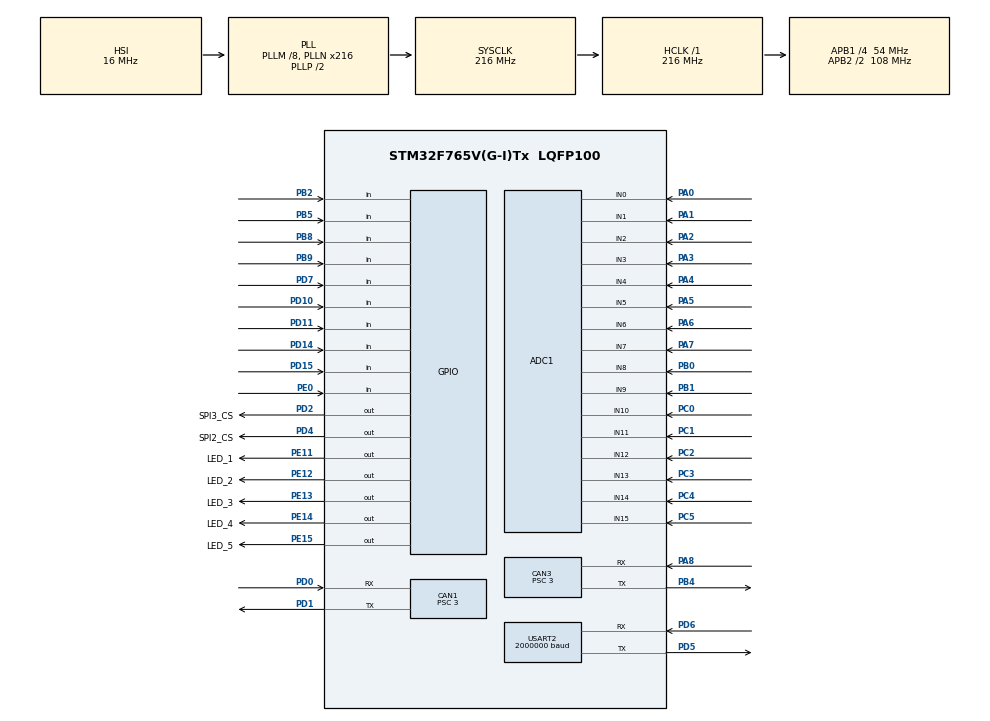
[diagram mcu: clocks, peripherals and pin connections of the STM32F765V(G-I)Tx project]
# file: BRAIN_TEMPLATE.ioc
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ADC1.Channel-6\#ChannelRegularConversion=ADC_CHANNEL_10
ADC1.NbrOfConversionFlag=1
ADC1.Rank-6\#ChannelRegularConversion=1
ADC1.SamplingTime-6\#ChannelRegularConversion=ADC_SAMPLETIME_3CYCLES
ADC1.master=1
CAN1.BS1=CAN_BS1_15TQ
CAN1.BS2=CAN_BS2_2TQ
CAN1.CalculateTimeQuantum=55.55555555555556
CAN1.NART=ENABLE
CAN1.Prescaler=3
CAN3.BS1=CAN_BS1_15TQ
CAN3.BS2=CAN_BS2_2TQ
CAN3.CalculateTimeQuantum=55.55555555555556
CAN3.NART=ENABLE
CAN3.Prescaler=3
Mcu.Family=STM32F7
Mcu.Name=STM32F765V(G-I)Tx
Mcu.Package=LQFP100
NVIC.CAN1_RX0_IRQn=true\:0\:0\:false\:true\:true\:2\:true\:true
NVIC.CAN1_RX1_IRQn=true\:0\:0\:false\:true\:true\:3\:true\:true
NVIC.CAN1_SCE_IRQn=true\:0\:0\:false\:true\:true\:4\:true\:true
NVIC.CAN1_TX_IRQn=true\:0\:0\:false\:true\:true\:1\:true\:true
NVIC.CAN3_RX0_IRQn=true\:0\:0\:false\:true\:true\:6\:true\:true
NVIC.CAN3_RX1_IRQn=true\:0\:0\:false\:true\:true\:8\:true\:true
NVIC.CAN3_SCE_IRQn=true\:0\:0\:false\:true\:true\:7\:true\:true
NVIC.CAN3_TX_IRQn=true\:0\:0\:false\:true\:true\:5\:true\:true
NVIC.PriorityGroup=NVIC_PRIORITYGROUP_4
PA0/WKUP.Signal=ADCx_IN0
PA1.Signal=ADCx_IN1
PA10.Signal=USART1_RX
PA13.Signal=SYS_JTMS-SWDIO
PA14.Signal=SYS_JTCK-SWCLK
PA2.Signal=ADCx_IN2
PA3.Signal=ADCx_IN3
PA4.Signal=ADCx_IN4
PA5.Signal=ADCx_IN5
PA6.Signal=ADCx_IN6
PA7.Signal=ADCx_IN7
PA8.Mode=Master
PA8.Signal=CAN3_RX
PA9.Signal=USART1_TX
PB0.Signal=ADCx_IN8
PB1.Signal=ADCx_IN9
PB10.Signal=I2C2_SCL
PB11.Signal=I2C2_SDA
PB14.Signal=SPI2_MISO
PB15.Signal=SPI2_MOSI
PB2.Signal=GPIO_Input
PB3.Signal=SYS_JTDO-SWO
PB4.Mode=Master
PB4.Signal=CAN3_TX
PB5.Signal=GPIO_Input
PB6.Signal=I2C1_SCL
PB7.Signal=I2C1_SDA
PB8.Signal=GPIO_Input
PB9.Signal=GPIO_Input
PC0.Signal=ADCx_IN10
PC1.Signal=ADCx_IN11
PC10.Signal=SPI3_SCK
PC11.Signal=SPI3_MISO
PC12.Signal=SPI3_MOSI
PC2.Signal=ADCx_IN12
PC3.Signal=ADCx_IN13
PC4.Signal=ADCx_IN14
PC5.Signal=ADCx_IN15
PC6.Signal=USART6_TX
PC7.Signal=USART6_RX
PD0.Mode=Master
PD0.Signal=CAN1_RX
PD1.Mode=Master
PD1.Signal=CAN1_TX
PD10.Signal=GPIO_Input
PD11.Signal=GPIO_Input
PD12.Signal=I2C4_SCL
PD13.Signal=I2C4_SDA
PD14.Signal=GPIO_Input
PD15.Signal=GPIO_Input
PD2.GPIO_Label=SPI3_CS
PD2.Signal=GPIO_Output
PD3.Signal=I2S2_CK
PD4.GPIO_Label=SPI2_CS
PD4.Signal=GPIO_Output
PD5.Mode=Asynchronous
PD5.Signal=USART2_TX
PD6.Mode=Asynchronous
PD6.Signal=USART2_RX
PD7.Signal=GPIO_Input
PE0.Signal=GPIO_Input
PE1.Signal=UART8_TX
PE11.GPIO_Label=LED_1
PE11.Signal=GPIO_Output
PE12.GPIO_Label=LED_2
PE12.Signal=GPIO_Output
PE13.GPIO_Label=LED_3
PE13.Signal=GPIO_Output
PE14.GPIO_Label=LED_4
PE14.Signal=GPIO_Output
PE15.GPIO_Label=LED_5
PE15.Signal=GPIO_Output
PE2.Signal=SPI4_SCK
PE5.Signal=SPI4_MISO
PE6.Signal=SPI4_MOSI
ProjectManager.HeapSize=0x200
ProjectManager.StackSize=0x400
ProjectManager.TargetToolchain=Makefile
RCC.AHBFreq_Value=216000000
RCC.APB1CLKDivider=RCC_HCLK_DIV4
RCC.APB1Freq_Value=54000000
RCC.APB1TimFreq_Value=108000000
RCC.APB2CLKDivider=RCC_HCLK_DIV2
RCC.APB2Freq_Value=108000000
RCC.APB2TimFreq_Value=216000000
RCC.CortexFreq_Value=216000000
RCC.HCLKFreq_Value=216000000
RCC.HSE_VALUE=25000000
RCC.HSI_VALUE=16000000
RCC.LSE_VALUE=32768
RCC.PLLM=8
RCC.PLLN=216
RCC.SYSCLKFreq_VALUE=216000000
RCC.SYSCLKSource=RCC_SYSCLKSOURCE_PLLCLK
RCC.USBFreq_Value=216000000
RCC.VCOOutputFreq_Value=432000000
SH.ADCx_IN0.0=ADC1_IN0,IN0
SH.ADCx_IN1.0=ADC1_IN1,IN1
SH.ADCx_IN10.0=ADC1_IN10,IN10
SH.ADCx_IN11.0=ADC1_IN11,IN11
SH.ADCx_IN12.0=ADC1_IN12,IN12
SH.ADCx_IN13.0=ADC1_IN13,IN13
SH.ADCx_IN14.0=ADC1_IN14,IN14
SH.ADCx_IN15.0=ADC1_IN15,IN15
SH.ADCx_IN2.0=ADC1_IN2,IN2
SH.ADCx_IN3.0=ADC1_IN3,IN3
SH.ADCx_IN4.0=ADC1_IN4,IN4
SH.ADCx_IN5.0=ADC1_IN5,IN5
SH.ADCx_IN6.0=ADC1_IN6,IN6
SH.ADCx_IN7.0=ADC1_IN7,IN7
SH.ADCx_IN8.0=ADC1_IN8,IN8
SH.ADCx_IN9.0=ADC1_IN9,IN9
USART2.BaudRate=2000000
USART2.VirtualMode-Asynchronous=VM_ASYNC
board=custom

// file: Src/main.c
/* USER CODE BEGIN Header */
/**
  ******************************************************************************
  * @file           : main.c
  * @brief          : Main program body
  ******************************************************************************
  * @attention
  *
  * <h2><center>&copy; Copyright (c) 2019 STMicroelectronics.
  * All rights reserved.</center></h2>
  *
  * This software component is licensed by ST under BSD 3-Clause license,
  * the "License"; You may not use this file except in compliance with the
  * License. You may obtain a copy of the License at:
  *                        opensource.org/licenses/BSD-3-Clause
  *
  ******************************************************************************
  */
/* USER CODE END Header */

#include "main.h"

ADC_HandleTypeDef hadc1;

CAN_HandleTypeDef hcan1;
CAN_HandleTypeDef hcan3;

UART_HandleTypeDef huart2;

void SystemClock_Config(void);
static void MX_GPIO_Init(void);
static void MX_ADC1_Init(void);
static void MX_CAN1_Init(void);
static void MX_CAN3_Init(void);
static void MX_USART2_UART_Init(void);
static void MX_NVIC_Init(void);

int main(void)
{

  /* MCU Configuration--------------------------------------------------------*/

  /* Reset of all peripherals, Initializes the Flash interface and the Systick. */
  HAL_Init();

  /* Configure the system clock */
  SystemClock_Config();

  /* Initialize all configured peripherals */
  MX_GPIO_Init();
  MX_ADC1_Init();
  MX_CAN1_Init();
  MX_CAN3_Init();
  MX_USART2_UART_Init();

  /* Initialize interrupts */
  MX_NVIC_Init();
  /* USER CODE BEGIN 2 */

  for(int i = 0; i < 10; i++){
    HAL_GPIO_TogglePin(LED_1_GPIO_Port, LED_1_Pin);
    HAL_GPIO_TogglePin(LED_2_GPIO_Port, LED_2_Pin);
    HAL_GPIO_TogglePin(LED_3_GPIO_Port, LED_3_Pin);
    HAL_GPIO_TogglePin(LED_4_GPIO_Port, LED_4_Pin);
    HAL_GPIO_TogglePin(LED_5_GPIO_Port, LED_5_Pin);
    HAL_Delay(50);
  }
  /* USER CODE END 2 */

  /* Infinite loop */
  /* USER CODE BEGIN WHILE */
  while (1)
  {
    HAL_GPIO_TogglePin(LED_1_GPIO_Port, LED_1_Pin);
    HAL_GPIO_TogglePin(LED_2_GPIO_Port, LED_2_Pin);
    HAL_GPIO_TogglePin(LED_3_GPIO_Port, LED_3_Pin);
    HAL_GPIO_TogglePin(LED_4_GPIO_Port, LED_4_Pin);
    HAL_GPIO_TogglePin(LED_5_GPIO_Port, LED_5_Pin);
    HAL_Delay(500);
    /* USER CODE END WHILE */

  }
}

void SystemClock_Config(void)
{
  RCC_OscInitTypeDef RCC_OscInitStruct = {0};
  RCC_ClkInitTypeDef RCC_ClkInitStruct = {0};
  RCC_PeriphCLKInitTypeDef PeriphClkInitStruct = {0};

  /** Configure the main internal regulator output voltage
  */
  __HAL_RCC_PWR_CLK_ENABLE();
  __HAL_PWR_VOLTAGESCALING_CONFIG(PWR_REGULATOR_VOLTAGE_SCALE1);
  /** Initializes the CPU, AHB and APB busses clocks
  */
  RCC_OscInitStruct.OscillatorType = RCC_OSCILLATORTYPE_HSI;
  RCC_OscInitStruct.HSIState = RCC_HSI_ON;
  RCC_OscInitStruct.HSICalibrationValue = RCC_HSICALIBRATION_DEFAULT;
  RCC_OscInitStruct.PLL.PLLState = RCC_PLL_ON;
  RCC_OscInitStruct.PLL.PLLSource = RCC_PLLSOURCE_HSI;
  RCC_OscInitStruct.PLL.PLLM = 8;
  RCC_OscInitStruct.PLL.PLLN = 216;
  RCC_OscInitStruct.PLL.PLLP = RCC_PLLP_DIV2;
  RCC_OscInitStruct.PLL.PLLQ = 2;
  if (HAL_RCC_OscConfig(&RCC_OscInitStruct) != HAL_OK)
  {
    Error_Handler();
  }
  /** Activate the Over-Drive mode
  */
  if (HAL_PWREx_EnableOverDrive() != HAL_OK)
  {
    Error_Handler();
  }
  /** Initializes the CPU, AHB and APB busses clocks
  */
  RCC_ClkInitStruct.ClockType = RCC_CLOCKTYPE_HCLK|RCC_CLOCKTYPE_SYSCLK
                              |RCC_CLOCKTYPE_PCLK1|RCC_CLOCKTYPE_PCLK2;
  RCC_ClkInitStruct.SYSCLKSource = RCC_SYSCLKSOURCE_PLLCLK;
  RCC_ClkInitStruct.AHBCLKDivider = RCC_SYSCLK_DIV1;
  RCC_ClkInitStruct.APB1CLKDivider = RCC_HCLK_DIV4;
  RCC_ClkInitStruct.APB2CLKDivider = RCC_HCLK_DIV2;

  if (HAL_RCC_ClockConfig(&RCC_ClkInitStruct, FLASH_LATENCY_7) != HAL_OK)
  {
    Error_Handler();
  }
  PeriphClkInitStruct.PeriphClockSelection = RCC_PERIPHCLK_USART2;
  PeriphClkInitStruct.Usart2ClockSelection = RCC_USART2CLKSOURCE_PCLK1;
  if (HAL_RCCEx_PeriphCLKConfig(&PeriphClkInitStruct) != HAL_OK)
  {
    Error_Handler();
  }
}

/**
  * @brief NVIC Configuration.
  * @retval None
  */
static void MX_NVIC_Init(void)
{
  /* CAN1_TX_IRQn interrupt configuration */
  HAL_NVIC_SetPriority(CAN1_TX_IRQn, 0, 0);
  HAL_NVIC_EnableIRQ(CAN1_TX_IRQn);
  /* CAN1_RX0_IRQn interrupt configuration */
  HAL_NVIC_SetPriority(CAN1_RX0_IRQn, 0, 0);
  HAL_NVIC_EnableIRQ(CAN1_RX0_IRQn);
  /* CAN1_RX1_IRQn interrupt configuration */
  HAL_NVIC_SetPriority(CAN1_RX1_IRQn, 0, 0);
  HAL_NVIC_EnableIRQ(CAN1_RX1_IRQn);
  /* CAN1_SCE_IRQn interrupt configuration */
  HAL_NVIC_SetPriority(CAN1_SCE_IRQn, 0, 0);
  HAL_NVIC_EnableIRQ(CAN1_SCE_IRQn);
  /* CAN3_TX_IRQn interrupt configuration */
  HAL_NVIC_SetPriority(CAN3_TX_IRQn, 0, 0);
  HAL_NVIC_EnableIRQ(CAN3_TX_IRQn);
  /* CAN3_RX0_IRQn interrupt configuration */
  HAL_NVIC_SetPriority(CAN3_RX0_IRQn, 0, 0);
  HAL_NVIC_EnableIRQ(CAN3_RX0_IRQn);
  /* CAN3_SCE_IRQn interrupt configuration */
  HAL_NVIC_SetPriority(CAN3_SCE_IRQn, 0, 0);
  HAL_NVIC_EnableIRQ(CAN3_SCE_IRQn);
  /* CAN3_RX1_IRQn interrupt configuration */
  HAL_NVIC_SetPriority(CAN3_RX1_IRQn, 0, 0);
  HAL_NVIC_EnableIRQ(CAN3_RX1_IRQn);
}

static void MX_ADC1_Init(void)
{

  ADC_ChannelConfTypeDef sConfig = {0};

  /** Configure the global features of the ADC (Clock, Resolution, Data Alignment and number of conversion)
  */
  hadc1.Instance = ADC1;
  hadc1.Init.ClockPrescaler = ADC_CLOCK_SYNC_PCLK_DIV4;
  hadc1.Init.Resolution = ADC_RESOLUTION_12B;
  hadc1.Init.ScanConvMode = ADC_SCAN_DISABLE;
  hadc1.Init.ContinuousConvMode = DISABLE;
  hadc1.Init.DiscontinuousConvMode = DISABLE;
  hadc1.Init.ExternalTrigConvEdge = ADC_EXTERNALTRIGCONVEDGE_NONE;
  hadc1.Init.ExternalTrigConv = ADC_SOFTWARE_START;
  hadc1.Init.DataAlign = ADC_DATAALIGN_RIGHT;
  hadc1.Init.NbrOfConversion = 1;
  hadc1.Init.DMAContinuousRequests = DISABLE;
  hadc1.Init.EOCSelection = ADC_EOC_SINGLE_CONV;
  if (HAL_ADC_Init(&hadc1) != HAL_OK)
  {
    Error_Handler();
  }
  /** Configure for the selected ADC regular channel its corresponding rank in the sequencer and its sample time.
  */
  sConfig.Channel = ADC_CHANNEL_10;
  sConfig.Rank = ADC_REGULAR_RANK_1;
  sConfig.SamplingTime = ADC_SAMPLETIME_3CYCLES;
  if (HAL_ADC_ConfigChannel(&hadc1, &sConfig) != HAL_OK)
  {
    Error_Handler();
  }

}

static void MX_CAN1_Init(void)
{

  hcan1.Instance = CAN1;
  hcan1.Init.Prescaler = 3;
  hcan1.Init.Mode = CAN_MODE_NORMAL;
  hcan1.Init.SyncJumpWidth = CAN_SJW_1TQ;
  hcan1.Init.TimeSeg1 = CAN_BS1_15TQ;
  hcan1.Init.TimeSeg2 = CAN_BS2_2TQ;
  hcan1.Init.TimeTriggeredMode = DISABLE;
  hcan1.Init.AutoBusOff = DISABLE;
  hcan1.Init.AutoWakeUp = DISABLE;
  hcan1.Init.AutoRetransmission = ENABLE;
  hcan1.Init.ReceiveFifoLocked = DISABLE;
  hcan1.Init.TransmitFifoPriority = DISABLE;
  if (HAL_CAN_Init(&hcan1) != HAL_OK)
  {
    Error_Handler();
  }

}

static void MX_CAN3_Init(void)
{

  hcan3.Instance = CAN3;
  hcan3.Init.Prescaler = 3;
  hcan3.Init.Mode = CAN_MODE_NORMAL;
  hcan3.Init.SyncJumpWidth = CAN_SJW_1TQ;
  hcan3.Init.TimeSeg1 = CAN_BS1_15TQ;
  hcan3.Init.TimeSeg2 = CAN_BS2_2TQ;
  hcan3.Init.TimeTriggeredMode = DISABLE;
  hcan3.Init.AutoBusOff = DISABLE;
  hcan3.Init.AutoWakeUp = DISABLE;
  hcan3.Init.AutoRetransmission = ENABLE;
  hcan3.Init.ReceiveFifoLocked = DISABLE;
  hcan3.Init.TransmitFifoPriority = DISABLE;
  if (HAL_CAN_Init(&hcan3) != HAL_OK)
  {
    Error_Handler();
  }

}

static void MX_USART2_UART_Init(void)
{

  huart2.Instance = USART2;
  huart2.Init.BaudRate = 2000000;
  huart2.Init.WordLength = UART_WORDLENGTH_8B;
  huart2.Init.StopBits = UART_STOPBITS_1;
  huart2.Init.Parity = UART_PARITY_NONE;
  huart2.Init.Mode = UART_MODE_TX_RX;
  huart2.Init.HwFlowCtl = UART_HWCONTROL_NONE;
  huart2.Init.OverSampling = UART_OVERSAMPLING_16;
  huart2.Init.OneBitSampling = UART_ONE_BIT_SAMPLE_DISABLE;
  huart2.AdvancedInit.AdvFeatureInit = UART_ADVFEATURE_NO_INIT;
  if (HAL_UART_Init(&huart2) != HAL_OK)
  {
    Error_Handler();
  }

}

static void MX_GPIO_Init(void)
{
  GPIO_InitTypeDef GPIO_InitStruct = {0};

  /* GPIO Ports Clock Enable */
  __HAL_RCC_GPIOE_CLK_ENABLE();
  __HAL_RCC_GPIOC_CLK_ENABLE();
  __HAL_RCC_GPIOA_CLK_ENABLE();
  __HAL_RCC_GPIOB_CLK_ENABLE();
  __HAL_RCC_GPIOD_CLK_ENABLE();

  /*Configure GPIO pin Output Level */
  HAL_GPIO_WritePin(GPIOE, LED_1_Pin|LED_2_Pin|LED_3_Pin|LED_4_Pin
                          |LED_5_Pin, GPIO_PIN_RESET);

  /*Configure GPIO pin Output Level */
  HAL_GPIO_WritePin(GPIOD, SPI3_CS_Pin|SPI2_CS_Pin, GPIO_PIN_RESET);

  /*Configure GPIO pins : PE2 PE5 PE6 */
  GPIO_InitStruct.Pin = GPIO_PIN_2|GPIO_PIN_5|GPIO_PIN_6;
  GPIO_InitStruct.Mode = GPIO_MODE_AF_PP;
  GPIO_InitStruct.Pull = GPIO_NOPULL;
  GPIO_InitStruct.Speed = GPIO_SPEED_FREQ_VERY_HIGH;
  GPIO_InitStruct.Alternate = GPIO_AF5_SPI4;
  HAL_GPIO_Init(GPIOE, &GPIO_InitStruct);

  /*Configure GPIO pins : PB2 PB5 PB8 PB9 */
  GPIO_InitStruct.Pin = GPIO_PIN_2|GPIO_PIN_5|GPIO_PIN_8|GPIO_PIN_9;
  GPIO_InitStruct.Mode = GPIO_MODE_INPUT;
  GPIO_InitStruct.Pull = GPIO_NOPULL;
  HAL_GPIO_Init(GPIOB, &GPIO_InitStruct);

  /*Configure GPIO pins : LED_1_Pin LED_2_Pin LED_3_Pin LED_4_Pin
                           LED_5_Pin */
  GPIO_InitStruct.Pin = LED_1_Pin|LED_2_Pin|LED_3_Pin|LED_4_Pin
                          |LED_5_Pin;
  GPIO_InitStruct.Mode = GPIO_MODE_OUTPUT_PP;
  GPIO_InitStruct.Pull = GPIO_NOPULL;
  GPIO_InitStruct.Speed = GPIO_SPEED_FREQ_LOW;
  HAL_GPIO_Init(GPIOE, &GPIO_InitStruct);

  /*Configure GPIO pins : PB10 PB11 */
  GPIO_InitStruct.Pin = GPIO_PIN_10|GPIO_PIN_11;
  GPIO_InitStruct.Mode = GPIO_MODE_AF_OD;
  GPIO_InitStruct.Pull = GPIO_PULLUP;
  GPIO_InitStruct.Speed = GPIO_SPEED_FREQ_VERY_HIGH;
  GPIO_InitStruct.Alternate = GPIO_AF4_I2C2;
  HAL_GPIO_Init(GPIOB, &GPIO_InitStruct);

  /*Configure GPIO pins : PB14 PB15 */
  GPIO_InitStruct.Pin = GPIO_PIN_14|GPIO_PIN_15;
  GPIO_InitStruct.Mode = GPIO_MODE_AF_PP;
  GPIO_InitStruct.Pull = GPIO_NOPULL;
  GPIO_InitStruct.Speed = GPIO_SPEED_FREQ_VERY_HIGH;
  GPIO_InitStruct.Alternate = GPIO_AF5_SPI2;
  HAL_GPIO_Init(GPIOB, &GPIO_InitStruct);

  /*Configure GPIO pins : PD10 PD11 PD14 PD15
                           PD7 */
  GPIO_InitStruct.Pin = GPIO_PIN_10|GPIO_PIN_11|GPIO_PIN_14|GPIO_PIN_15
                          |GPIO_PIN_7;
  GPIO_InitStruct.Mode = GPIO_MODE_INPUT;
  GPIO_InitStruct.Pull = GPIO_NOPULL;
  HAL_GPIO_Init(GPIOD, &GPIO_InitStruct);

  /*Configure GPIO pins : PD12 PD13 */
  GPIO_InitStruct.Pin = GPIO_PIN_12|GPIO_PIN_13;
  GPIO_InitStruct.Mode = GPIO_MODE_AF_OD;
  GPIO_InitStruct.Pull = GPIO_PULLUP;
  GPIO_InitStruct.Speed = GPIO_SPEED_FREQ_VERY_HIGH;
  GPIO_InitStruct.Alternate = GPIO_AF4_I2C4;
  HAL_GPIO_Init(GPIOD, &GPIO_InitStruct);

  /*Configure GPIO pins : PC6 PC7 */
  GPIO_InitStruct.Pin = GPIO_PIN_6|GPIO_PIN_7;
  GPIO_InitStruct.Mode = GPIO_MODE_AF_PP;
  GPIO_InitStruct.Pull = GPIO_NOPULL;
  GPIO_InitStruct.Speed = GPIO_SPEED_FREQ_VERY_HIGH;
  GPIO_InitStruct.Alternate = GPIO_AF8_USART6;
  HAL_GPIO_Init(GPIOC, &GPIO_InitStruct);

  /*Configure GPIO pins : PA9 PA10 */
  GPIO_InitStruct.Pin = GPIO_PIN_9|GPIO_PIN_10;
  GPIO_InitStruct.Mode = GPIO_MODE_AF_PP;
  GPIO_InitStruct.Pull = GPIO_NOPULL;
  GPIO_InitStruct.Speed = GPIO_SPEED_FREQ_VERY_HIGH;
  GPIO_InitStruct.Alternate = GPIO_AF7_USART1;
  HAL_GPIO_Init(GPIOA, &GPIO_InitStruct);

  /*Configure GPIO pins : PC10 PC11 PC12 */
  GPIO_InitStruct.Pin = GPIO_PIN_10|GPIO_PIN_11|GPIO_PIN_12;
  GPIO_InitStruct.Mode = GPIO_MODE_AF_PP;
  GPIO_InitStruct.Pull = GPIO_NOPULL;
  GPIO_InitStruct.Speed = GPIO_SPEED_FREQ_VERY_HIGH;
  GPIO_InitStruct.Alternate = GPIO_AF6_SPI3;
  HAL_GPIO_Init(GPIOC, &GPIO_InitStruct);

  /*Configure GPIO pins : SPI3_CS_Pin SPI2_CS_Pin */
  GPIO_InitStruct.Pin = SPI3_CS_Pin|SPI2_CS_Pin;
  GPIO_InitStruct.Mode = GPIO_MODE_OUTPUT_PP;
  GPIO_InitStruct.Pull = GPIO_NOPULL;
  GPIO_InitStruct.Speed = GPIO_SPEED_FREQ_LOW;
  HAL_GPIO_Init(GPIOD, &GPIO_InitStruct);

  /*Configure GPIO pin : PD3 */
  GPIO_InitStruct.Pin = GPIO_PIN_3;
  GPIO_InitStruct.Mode = GPIO_MODE_AF_PP;
  GPIO_InitStruct.Pull = GPIO_NOPULL;
  GPIO_InitStruct.Speed = GPIO_SPEED_FREQ_LOW;
  GPIO_InitStruct.Alternate = GPIO_AF5_SPI2;
  HAL_GPIO_Init(GPIOD, &GPIO_InitStruct);

  /*Configure GPIO pins : PB6 PB7 */
  GPIO_InitStruct.Pin = GPIO_PIN_6|GPIO_PIN_7;
  GPIO_InitStruct.Mode = GPIO_MODE_AF_OD;
  GPIO_InitStruct.Pull = GPIO_PULLUP;
  GPIO_InitStruct.Speed = GPIO_SPEED_FREQ_VERY_HIGH;
  GPIO_InitStruct.Alternate = GPIO_AF4_I2C1;
  HAL_GPIO_Init(GPIOB, &GPIO_InitStruct);

  /*Configure GPIO pin : PE0 */
  GPIO_InitStruct.Pin = GPIO_PIN_0;
  GPIO_InitStruct.Mode = GPIO_MODE_INPUT;
  GPIO_InitStruct.Pull = GPIO_NOPULL;
  HAL_GPIO_Init(GPIOE, &GPIO_InitStruct);

  /*Configure GPIO pin : PE1 */
  GPIO_InitStruct.Pin = GPIO_PIN_1;
  GPIO_InitStruct.Mode = GPIO_MODE_AF_PP;
  GPIO_InitStruct.Pull = GPIO_NOPULL;
  GPIO_InitStruct.Speed = GPIO_SPEED_FREQ_VERY_HIGH;
  GPIO_InitStruct.Alternate = GPIO_AF8_UART8;
  HAL_GPIO_Init(GPIOE, &GPIO_InitStruct);

}

void Error_Handler(void)
{
}

/************************ (C) COPYRIGHT STMicroelectronics *****END OF FILE****/
